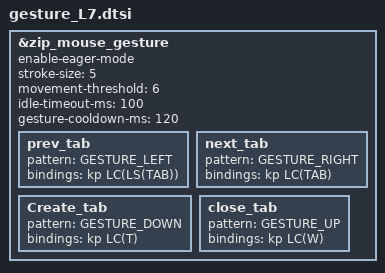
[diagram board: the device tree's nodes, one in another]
&zip_mouse_gesture {
    enable-eager-mode;
    stroke-size = <5>;
    movement-threshold = <6>;
    idle-timeout-ms = <100>;
    gesture-cooldown-ms = <120>;

    prev_tab    { pattern = <GESTURE_LEFT>;  bindings = <&kp LC(LS(TAB))>; };
    next_tab    { pattern = <GESTURE_RIGHT>; bindings = <&kp LC(TAB)>;     };
    Create_tab  { pattern = <GESTURE_DOWN>; bindings = <&kp LC(T)>;      };  // invert-y: 物理上 → GESTURE_DOWN
    close_tab   { pattern = <GESTURE_UP>;   bindings = <&kp LC(W)>;       };  // invert-y: 物理下 → GESTURE_UP
};
